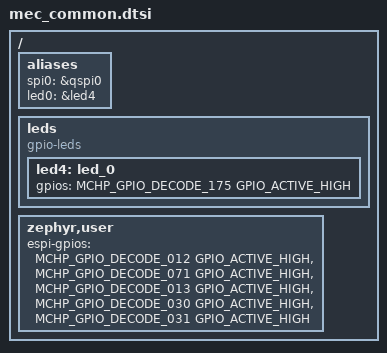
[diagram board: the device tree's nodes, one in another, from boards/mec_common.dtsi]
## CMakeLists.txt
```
# SPDX-License-Identifier: Apache-2.0

cmake_minimum_required(VERSION 3.20.0)

find_package(Zephyr REQUIRED HINTS $ENV{ZEPHYR_BASE})
project(espi_host_emu)

FILE(GLOB app_sources src/*.c)
target_sources(app PRIVATE ${app_sources})
```

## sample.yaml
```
sample:
  name: Exercise eSPI driver with an emulated eSPI host
tests:
  sample.boards.mec_assy6906.espi_host_emu:
    build_only: true
    platform_allow:
      - mec_assy6906_mech1723nlj
      - mec_assy6906_mech1723nsz
    tags: drivers espi
```

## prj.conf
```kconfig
CONFIG_LOG=y
CONFIG_LOG_MODE_IMMEDIATE=y
#CONFIG_LOG_MODE_MINIMAL=y
# !!! WARNING: deferred and buffer size not working.
# !!! log_panic() does not output messages.
#CONFIG_LOG_MODE_DEFERRED=y
#CONFIG_LOG_BUFFER_SIZE=4096
#CONFIG_LOG_BACKEND_SWO=y
#CONFIG_LOG_BACKEND_SWO_FREQ_HZ=4000000

CONFIG_GPIO=y
CONFIG_PINCTRL=y
CONFIG_LED=y
CONFIG_SPI=y
CONFIG_SPI_EXTENDED_MODES=y
CONFIG_SPI_MEC5_QSPI_INTERRUPT=n
CONFIG_SERIAL=y
CONFIG_CONSOLE=y
CONFIG_UART_CONSOLE=y
CONFIG_I2C=y

CONFIG_PM=n

# CONFIG_APP_INVERT_ESPI_CS_N=y

# Help debug new code
# CONFIG_DEBUG_COREDUMP=y
# CONFIG_TRAP_UNALIGNED_ACCESS=y
# CONFIG_SOC_MEC5_DEBUG_AND_TRACING=y
# CONFIG_SOC_MEC5_DEBUG_AND_SWV_TRACING=y
#CONFIG_DEBUG=y
```

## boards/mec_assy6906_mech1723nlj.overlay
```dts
/*
 * Copyright (c) 2023 Microchip Technology Inc.
 *
 * SPDX-License-Identifier: Apache-2.0
 */

/* mec_assy6906 EVB with MEC1723N-LJ daughter card
 * MEC1723 does not have an internal SPI flash.
 * Connect QSPI to external shared SPI flash pins using SHD_nCS1.
 */

#include "mec_common.dtsi"

&pinctrl {
	qspi_shd_cs0_n_gpio055_sleep: qspi_shd_cs0_n_gpio055_sleep {
		pinmux = < MCHP_XEC_PINMUX(055, MCHP_AF2) >;
		low-power-enable;
	};
};

&qspi0 {
	status = "okay";
	pinctrl-0 = < &qspi_shd_cs0_n_gpio055_sleep
		      &qspi_shd_cs1_n_gpio002
		      &qspi_shd_clk_gpio056
		      &qspi_shd_io0_gpio223
		      &qspi_shd_io1_gpio224
		      &qspi_shd_io2_gpio227
		      &qspi_shd_io3_gpio016 >;
	pinctrl-names = "default";
};
```

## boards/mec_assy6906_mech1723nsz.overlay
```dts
/*
 * Copyright (c) 2023 Microchip Technology Inc.
 *
 * SPDX-License-Identifier: Apache-2.0
 */

/* mec_assy6906 EVB with MEC1723N-SZ daughter card
 * MEC1723 does not have an internal SPI flash.
 * Connect QSPI to external shared SPI flash pins using SHD_nCS1.
 */

#include "mec_common.dtsi"

&pinctrl {
	qspi_shd_cs0_n_gpio055_sleep: qspi_shd_cs0_n_gpio055_sleep {
		pinmux = < MCHP_XEC_PINMUX(055, MCHP_AF2) >;
		low-power-enable;
	};
};

&qspi0 {
	status = "okay";
	pinctrl-0 = < &qspi_shd_cs0_n_gpio055_sleep
		      &qspi_shd_cs1_n_gpio002
		      &qspi_shd_clk_gpio056
		      &qspi_shd_io0_gpio223
		      &qspi_shd_io1_gpio224
		      &qspi_shd_io2_gpio227
		      &qspi_shd_io3_gpio016 >;
	pinctrl-names = "default";
};
```

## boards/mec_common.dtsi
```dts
/*
 * Copyright (c) 2023 Microchip Technology Inc.
 *
 * SPDX-License-Identifier: Apache-2.0
 */

#include <zephyr/dt-bindings/gpio/gpio.h>
#include <zephyr/dt-bindings/gpio/microchip-xec-gpio.h>
#include <zephyr/dt-bindings/espi/mchp-mec5-espi.h>

/* Sample for MEC_ASSY6906 board with MEC1723N LJ(176-pin) or SZ(144-pin) CPU card
 * Emulate eSPI using QSPI controller and QSPI SHD_xxx pins.
 * SHD_xxx pins are on VTR2 voltage domain.
 * ESPI pins are on VTR3 (+1.8V) voltage domain on all MEC parts.
 * Configure Assy6906 VTR2 for +1.8V
 * JP42 1-2, JP59 1-2, JP60 2-3, JP61 1-2, JP62 1-2
 *
 * QSPI SHD_xxx pin jumpers:
 * JP156 1-2 Select VTR2 for QSPI header J34
 * JP25 1-2 Select SHD_nCS1 for GPIO002
 * JP23 3x6 2-3, 5-6, 8-9, 11-12, 14-15, 17-18 Select SHD_CLK, SHD_IOn, SHD_nCS0 pins
 *
 * Assy6906 J34 QSPI SHD/PVT SPI header J34
 * We choose SHD_nCS1 because it is not used as a strap.
 * pins 19,20 = VTR2
 * pins 1,5,17,18 = GND		GND
 * pin 10 SHD_nCS1		ESPI_nCS
 * pin 2  SHD_CLK		ESPI_CLK
 * pin 6  SHD_IO0		ESPI_IO0
 * pin 7  SHD_IO1		ESPI_IO1
 * pin 8  SHD_IO2		ESPI_IO2
 * pin 9  SHD_IO3		ESPI_IO3
 *
 * GPIO012(VTR2) J19-3		ESPI_nRESET
 *   output init value = High
 *
 * GPIO013(VTR2) J19-1		ESPI_nALERT
 *   output init value = High
 *
 * NOTE1: Target EVB has 10K pull-ups to VTR3 on all ESPI_xxx pins.
 * Do not enable pull-ups on Assy6906 for these pins.
 * NOTE2: eSPI Target will be configured to use its default in-band reset
 * on ESPI_IO1.  ESPI_nALERT may be used for debug.
 *
 * Emulated Host to Target VCC_PWRGD
 * GPIO030 (VTR1) on J9-1 or J40-6
 * No not install JP77 1-2 7.5K pull-up.
 * Configure GPIO030 as GPIO output initial state = Low
 *
 * Target Ready Input active Low
 * GPIO031 (VTR1) on J40-7
 * Install JP71 21-22 pull-up to VTR1
 * Configure GPIO031 as GPIO input
 *
 */

/ {
	aliases {
		spi0 = &qspi0;
		led0 = &led4;
	};

	leds {
		compatible = "gpio-leds";
		led4: led_0 {
			gpios = <MCHP_GPIO_DECODE_175 GPIO_ACTIVE_HIGH>;
		};
	};

	/* zephyr,user is a special case node for application & test use
	 * This node does not require a YAML binding file.
	 * espi-gpio pins
	 * index 0 = pin connected to ESPI_nRESET allowing app to control reset.
	 * index 1 = eSPI IO[1] GPIO used as eSPI ALERT. eSPI Target controller
	 * drives this pin low when it requires attention. Note: Target can drive
	 * eSPI ALERT pin when eSPI nCS is not asserted.
	 * index 2 = GPIO063 unused dedicated eSPI_nALERT pin. We use as GPIO to
	 * help measure code sequences.
	 * index 3 = GPIO030 used as GPIO output Host-to-Target VCC_PWRGD
	 * index 4 = GPIO031 used as GPIO input Target-nReady
	 * In application code use GPIO_DT_SPEC_GET_BY_IDX() macro.
	 */
	zephyr,user {
		espi-gpios = <MCHP_GPIO_DECODE_012 GPIO_ACTIVE_HIGH>,
			     <MCHP_GPIO_DECODE_071 GPIO_ACTIVE_HIGH>,
			     <MCHP_GPIO_DECODE_013 GPIO_ACTIVE_HIGH>,
			     <MCHP_GPIO_DECODE_030 GPIO_ACTIVE_HIGH>,
			     <MCHP_GPIO_DECODE_031 GPIO_ACTIVE_HIGH>;
	};
};
```

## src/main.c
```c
/*
 * Copyright (c) 2024 Microchip Technology, Inc.
 *
 * SPDX-License-Identifier: Apache-2.0
 */

#include <errno.h>
#include <stdint.h>
#include <string.h>
#include <soc.h>
#include <mec_pcr_api.h>

#include <zephyr/device.h>
#include <zephyr/devicetree.h>
#include <zephyr/kernel.h>
#include <zephyr/drivers/espi.h>
#include <zephyr/drivers/gpio.h>
#include <zephyr/drivers/i2c.h>
#include <zephyr/drivers/led.h>
#include <zephyr/drivers/pinctrl.h>
#include <zephyr/drivers/spi.h>
#include <zephyr/sys/sys_io.h>

#include <zephyr/logging/log_ctrl.h>
#include <zephyr/logging/log.h>
LOG_MODULE_REGISTER(app, CONFIG_LOG_DEFAULT_LEVEL);

#include "espi_debug.h"
#include "espi_hc_emu.h"

struct espi_status_data {
	void *buf;
	uint32_t bufsz;
	uint32_t nitems;
};

#define APP_FLAG_GET_STATUS_LOOP BIT(0)

static volatile uint32_t app_flags;
static volatile uint32_t spin_val;
static volatile int ret_val;
static volatile int app_main_exit;

static struct espi_status_data esd;
static struct espi_hc_context hc;
/* eSPI specification: maximum 64 VWire groups */
/* static struct espi_hc_vw hcvw[64]; */
static struct espi_hc_vw hcvw2[64];

#define ESPI_CHAN_READY_PC_IDX 0
#define ESPI_CHAN_READY_VW_IDX 1
#define ESPI_CHAN_READY_OOB_IDX 2
#define ESPI_CHAN_READY_FC_IDX 3
volatile uint8_t chan_ready[4];

static uint8_t c2t_vw_host_idxs[] = {
	0x02u, 0x03u, 0x07u, 0x41u, 0x42u, 0x43u, 0x44u, 0x47u, 0x4au
};

static void spin_on(uint32_t id, int rval);
static int wait_espi_chan_ready(struct espi_hc_context *pch, uint16_t cfgid, int timeout_cnt);
int app_process_espi_status(struct espi_hc_context *hc, uint16_t espi_status,
			    struct espi_status_data *data);

int main(void)
{
	int ret = 0;
	struct espi_hc_vw vwg = {0};
	uint32_t io_addr_len = 0;
	uint32_t io_data = 0;
	uint32_t chan_config = 0;
	uint16_t cfgid = 0;
	uint16_t cmd_status = 0;

	LOG_INF("MEC5 eSPI Host Controller emulation for board: %s", DT_N_COMPAT_MODEL_IDX_0);

	ret = espi_hc_ctx_emu_init(&hc);
	if (ret) {
		LOG_ERR("eSPI HC CTX EMU init error %d", ret);
		spin_on((uint32_t)__LINE__, ret);
		goto app_exit;
	}

	LOG_INF("Init eSPI HC emulation using QSPI0");
	ret = espi_hc_emu_init(MHZ(4));
	if (ret) {
		spin_on((uint32_t)__LINE__, ret);
		goto app_exit;
	}

	LOG_INF("Wait for Target nREADY");
	do {
		ret = espi_hc_emu_is_target_ready();
	} while (ret == 0);

	LOG_INF("Target signalled Ready. De-assert ESPI_nRESET and send GET_CONFIG");
	ret = espi_hc_ctx_emu_ctrl(&hc, 1);
	if (ret) {
		LOG_ERR("Error eSPI HC emu control (enable)");
		spin_on((uint32_t)__LINE__, ret);
		goto app_exit;
	}

	/* espi_hc_emu_espi_reset_n(1); */

	LOG_INF("Delay 100 ms to allow Target to print debug messages");
	k_sleep(K_MSEC(100));

	/* Get eSPI Device ID */
	LOG_INF("Read eSPI Device ID from Target");
	cfgid = ESPI_GET_CONFIG_DEV_ID;
	ret = espi_hc_ctx_emu_get_config(&hc, cfgid);
	if (ret) {
		LOG_ERR("FAIL: GET_CONFIG %u err (%d)", cfgid, ret);
		spin_on((uint32_t)__LINE__, ret);
		goto app_exit;
	}
	espi_debug_print_cap_word(cfgid, hc.version_id);
	espi_debug_pr_status(hc.pkt_status);

	LOG_INF("Read General Capabilities from Target");
	cfgid = ESPI_GET_CONFIG_GLB_CAP;
	ret = espi_hc_ctx_emu_get_config(&hc, cfgid);
	if (ret) {
		LOG_ERR("FAIL: GET_CONFIG %u err (%d)", cfgid, ret);
		spin_on((uint32_t)__LINE__, ret);
		goto app_exit;
	}
	espi_debug_print_cap_word(cfgid, hc.global_cap_cfg);
	espi_debug_pr_status(hc.pkt_status);

	if ((hc.global_cap_cfg & 0xf) != 0xfu) {
		LOG_ERR("PC, VW, OOB, FC are not all supported!");
		spin_on((uint32_t)__LINE__, ret);
		goto app_exit;
	}

	/* Read VW Capabilities from Target */
	LOG_INF("Read VWire Capabilities from Target");
	cfgid = ESPI_GET_CONFIG_VW_CAP;
	ret = espi_hc_ctx_emu_get_config(&hc, cfgid);
	if (ret) {
		LOG_ERR("FAIL: GET_CONFIG %u err (%d)", cfgid, ret);
		spin_on((uint32_t)__LINE__, ret);
		goto app_exit;
	}
	espi_debug_print_cap_word(cfgid, hc.vw_cap_cfg);
	espi_debug_pr_status(hc.pkt_status);

	/* Update VW Cap-Config
	 * Set Selected number of VW groups = Supported
	 * Enable VW Channel
	 * b[21:16] = operating maximum number of VW groups (R/W)
	 * b[13:8] = maximum number of VW groups the Target HW supports (R/O)
	 * b[1] = VW Channel Ready from Target (R/O)
	 * b[0] = VW Channel Enable set by Host (R/W)
	 */
	LOG_INF("Update VW Cap/Cfg: Set max supported VW groups to 8 and enable VW channel");
	chan_config = hc.vw_cap_cfg;
	chan_config &= ~(0x3fu << 16);
	chan_config |= (0x08u << 16); /* Set operating max to 8 VW groups */
	chan_config |= BIT(0); /* enable VW channel */
	LOG_INF("New VW Caps/Cfg = 0x%08x", chan_config);

	cfgid = ESPI_GET_CONFIG_VW_CAP;
	ret = espi_hc_ctx_emu_set_config(&hc, cfgid, chan_config);
	if (ret) {
		LOG_ERR("FAIL: sET_CONFIG %u err (%d)", cfgid, ret);
		spin_on((uint32_t)__LINE__, ret);
		goto app_exit;
	}
	espi_debug_pr_status(hc.pkt_status);

	LOG_INF("Poll reading VW Config until Target sets VW Ready");
	ret = wait_espi_chan_ready(&hc, cfgid, -1);
	if (ret) {
		goto app_exit;
	}

	espi_debug_print_cap_word(cfgid, hc.vw_cap_cfg);

	LOG_INF("Issue GET_STATUS");
	ret = espi_hc_ctx_get_status(&hc);
	if (ret) {
		LOG_ERR("GET_STATUS failed (%d)", ret);
		spin_on((uint32_t)__LINE__, ret);
		goto app_exit;
	}
	espi_debug_pr_status(hc.pkt_status);

	esd.buf = &hcvw2;
	esd.bufsz = sizeof(hcvw2);
	esd.nitems = 0u;
	ret = app_process_espi_status(&hc, hc.pkt_status, &esd);
	if (ret) {
		LOG_ERR("App process eSPI status: %d", ret);
		spin_on((uint32_t)__LINE__, ret);
		goto app_exit;
	}

	LOG_INF("Read OOB Channel configuration from Target");
	cfgid = ESPI_GET_CONFIG_OOB_CAP;
	ret = espi_hc_ctx_emu_get_config(&hc, cfgid);
	if (ret) {
		LOG_ERR("FAIL: GET_CONFIG %u err (%d)", cfgid, ret);
		spin_on((uint32_t)__LINE__, ret);
		goto app_exit;
	}
	espi_debug_print_cap_word(cfgid, hc.oob_cap_cfg);
	espi_debug_pr_status(hc.pkt_status);

	/* Enable OOB channel with maximum packet size 64 bytes
	 * b[10:8] = OOB message max. payload size (R/W)
	 * b[1] = ready (R/O)
	 * b[0] = enable (R/W)
	 */
	LOG_INF("Update OOB Config: Set max packet size to 64 bytes and enable OOB channel");
	chan_config = hc.oob_cap_cfg;
	LOG_INF("Current OOB Cap/Cfg = 0x%08x", chan_config);
	chan_config &= ~(0x7u << 8);
	chan_config |= (1u << 8); /* b[10:8]=001b is 64 bytes */
	chan_config |= BIT(0); /* enable OOB channel */
	LOG_INF("New OOB Caps/Cfg = 0x%08x", chan_config);

	cfgid = ESPI_GET_CONFIG_OOB_CAP;
	ret = espi_hc_ctx_emu_set_config(&hc, cfgid, chan_config);
	if (ret) {
		LOG_ERR("FAIL: SET_CONFIG %u err (%d)", cfgid, ret);
		spin_on((uint32_t)__LINE__, ret);
		goto app_exit;
	}
	espi_debug_pr_status(hc.pkt_status);

	LOG_INF("Poll reading OOB Config until Target sets OOB Ready");
	ret = wait_espi_chan_ready(&hc, cfgid, -1);
	if (ret) {
		goto app_exit;
	}

	LOG_INF("Issue GET_STATUS");
	ret = espi_hc_ctx_get_status(&hc);
	if (ret) {
		LOG_ERR("GET_STATUS failed (%d)", ret);
		spin_on((uint32_t)__LINE__, ret);
		goto app_exit;
	}
	espi_debug_pr_status(hc.pkt_status);

	esd.buf = &hcvw2;
	esd.bufsz = sizeof(hcvw2);
	esd.nitems = 0u;
	ret = app_process_espi_status(&hc, hc.pkt_status, &esd);
	if (ret) {
		LOG_ERR("App process eSPI status: %d", ret);
		spin_on((uint32_t)__LINE__, ret);
		goto app_exit;
	}

	/* Based on soft-straps reconfigure VW and OOB channels
	 * Increase VW operating max. groups to 0x3f
	 * No change to OOB. All we could do is increase max payload size.
	 */
	LOG_INF("Update VW Cap/Cfg: Set max supported VW groups to 0x3f");
	chan_config = hc.vw_cap_cfg;
	LOG_INF("Current VW Cap/Cfg = 0x%08x", chan_config);
	chan_config &= ~(0x3fu << 16);
	chan_config |= (0x3fu << 16); /* Set operating max to 63 VW groups */
	LOG_INF("New VW Caps/Cfg = 0x%08x", chan_config);

	cfgid = ESPI_GET_CONFIG_VW_CAP;
	ret = espi_hc_ctx_emu_set_config(&hc, cfgid, chan_config);
	if (ret) {
		LOG_ERR("FAIL: VW SET_CONFIG (%d)", ret);
		spin_on((uint32_t)__LINE__, ret);
		goto app_exit;
	}
	espi_debug_pr_status(hc.pkt_status);

	LOG_INF("Issue GET_STATUS");
	ret = espi_hc_ctx_get_status(&hc);
	if (ret) {
		LOG_ERR("GET_STATUS failed (%d)", ret);
		spin_on((uint32_t)__LINE__, ret);
		goto app_exit;
	}

	espi_debug_pr_status(hc.pkt_status);

	esd.buf = &hcvw2;
	esd.bufsz = sizeof(hcvw2);
	esd.nitems = 0u;
	ret = app_process_espi_status(&hc, hc.pkt_status, &esd);
	if (ret) {
		LOG_ERR("App process eSPI status: %d", ret);
		spin_on((uint32_t)__LINE__, ret);
		goto app_exit;
	}

	/* Enable Flash Channel
	 * Set b[14:12]=001b max. read request size of 64 bytes
	 * Set b[11]=0b CAFS
	 * Set b[10:8]=001b max max payload size of 64 bytes
	 * Set b[4:2]=001b flash block erase size 4KB
	 * b[1]=ready (R/O)
	 * b[0]=enable (R/W)
	 */
	LOG_INF("Update FC Cap/Cfg and enable");
	chan_config = hc.fc_cap_cfg;
	LOG_INF("Current FC Cap/Cfg = 0x%08x", chan_config);
	chan_config &= ~((0x7u << 12) | BIT(11) | (0x7u << 8) | (0x7u << 2));
	chan_config |= ((1u << 12) | (1u << 8) | (1u << 2) | BIT(0));
	LOG_INF("New VW Caps/Cfg = 0x%08x", chan_config);

	cfgid = ESPI_GET_CONFIG_FC_CAP;
	ret = espi_hc_ctx_emu_set_config(&hc, cfgid, chan_config);
	if (ret) {
		LOG_ERR("FAIL: FC SET_CONFIG (%d)", ret);
		spin_on((uint32_t)__LINE__, ret);
		goto app_exit;
	}
	espi_debug_pr_status(hc.pkt_status);

	LOG_INF("Poll reading FC Config until Target sets FC Ready");
	ret = wait_espi_chan_ready(&hc, cfgid, -1);
	if (ret) {
		goto app_exit;
	}

	LOG_INF("Issue GET_STATUS");
	ret = espi_hc_ctx_get_status(&hc);
	if (ret) {
		LOG_ERR("GET_STATUS failed (%d)", ret);
		spin_on((uint32_t)__LINE__, ret);
		goto app_exit;
	}
	espi_debug_pr_status(hc.pkt_status);

	esd.buf = &hcvw2;
	esd.bufsz = sizeof(hcvw2);
	esd.nitems = 0u;
	ret = app_process_espi_status(&hc, hc.pkt_status, &esd);
	if (ret) {
		LOG_ERR("App process eSPI status: %d", ret);
		spin_on((uint32_t)__LINE__, ret);
		goto app_exit;
	}

	k_sleep(K_MSEC(100));

	LOG_INF("Issue GET_STATUS");
	ret = espi_hc_ctx_get_status(&hc);
	if (ret) {
		LOG_ERR("GET_STATUS failed (%d)", ret);
		spin_on((uint32_t)__LINE__, ret);
		goto app_exit;
	}
	espi_debug_pr_status(hc.pkt_status);

	esd.buf = &hcvw2;
	esd.bufsz = sizeof(hcvw2);
	esd.nitems = 0u;
	ret = app_process_espi_status(&hc, hc.pkt_status, &esd);
	if (ret) {
		LOG_ERR("App process eSPI status: %d", ret);
		spin_on((uint32_t)__LINE__, ret);
		goto app_exit;
	}

	memset(&vwg, 0, sizeof(vwg));
	ret = espi_hc_get_vw_group_data(&hc, 5u, &vwg);
	if (ret) {
		LOG_ERR("Could not find VWire at Host Index 5h. (%d)", ret);
		spin_on((uint32_t)__LINE__, ret);
		goto app_exit;
	}

	if ((vwg.valid & (BIT(0) | BIT(3))) == (BIT(0) | BIT(3))) {
		LOG_INF("TARGET_BOOT_LOAD_DONE/STATUS are valid");
		LOG_INF("TARGET_BOOT_LOAD_DONE = %lu", (vwg.levels & BIT(0)));
		LOG_INF("TARGET_BOOT_LOAD_DONE_STATUS = %lu", ((vwg.levels & BIT(3)) >> 3));
		if ((vwg.levels & (BIT(0) | BIT(3))) == (BIT(0) | BIT(3))) {
			LOG_INF("Both VWires set by Target as expected");
		} else {
			LOG_ERR("Target did not set TARGET_BOOT_LOAD_DONE/STATUS "
				"to expected values");
			spin_on((uint32_t)__LINE__, ret);
			goto app_exit;
		}
	} else {
		LOG_ERR("TARGET_BOOT_LOAD_DONE/STATUS VWire values are not valid!");
		spin_on((uint32_t)__LINE__, ret);
		goto app_exit;
	}

	LOG_INF("Send default values of all Controller-to-Target VWires");
	ret = espi_hc_ctx_emu_put_mult_host_index(&hc, c2t_vw_host_idxs,
						  ARRAY_SIZE(c2t_vw_host_idxs),
						  ESPI_HC_EMU_PUT_VW_RST_VAL);
	if (ret) {
		LOG_ERR("C2T PUT_VW reset values failed (%d)", ret);
		spin_on((uint32_t)__LINE__, ret);
		goto app_exit;
	}

	LOG_INF("Issue GET_STATUS");
	ret = espi_hc_ctx_get_status(&hc);
	if (ret) {
		LOG_ERR("GET_STATUS failed (%d)", ret);
		spin_on((uint32_t)__LINE__, ret);
		goto app_exit;
	}
	espi_debug_pr_status(hc.pkt_status);

	esd.buf = &hcvw2;
	esd.bufsz = sizeof(hcvw2);
	esd.nitems = 0u;
	ret = app_process_espi_status(&hc, hc.pkt_status, &esd);
	if (ret) {
		LOG_ERR("App process eSPI status: %d", ret);
		spin_on((uint32_t)__LINE__, ret);
		goto app_exit;
	}

	/* Host set Target's VCC_PWRGD input High */
	ret = espi_hc_emu_vcc_pwrgd(1);
	if (ret) {
		LOG_ERR("Set VCC_PWRGD error: %d", ret);
		spin_on((uint32_t)__LINE__, ret);
		goto app_exit;
	}

	/* PUT_VWIRE SUS_WARN# = 1. Host index 0x41 bit 0 */
	LOG_INF("Host send C2T nSUS_WARN = 1");
	ret = espi_hc_set_ct_vwire(&hc, 0x41u, 0, 1);
	if (ret) {
		LOG_ERR("In HC CTX set SUS_WARN# = 1 error %d", ret);
		spin_on((uint32_t)__LINE__, ret);
		goto app_exit;
	}
	ret = espi_hc_ctx_emu_put_host_index(&hc, 0x41u);
	if (ret) {
		LOG_ERR("PUT_VW Host Index 0x41 error %d", ret);
		spin_on((uint32_t)__LINE__, ret);
		goto app_exit;
	}

	/* Send VW nSLP_S5=1. Host index 0x02 bit 2 */
	LOG_INF("Host send C2T nSLP_S5 = 1");
	ret = espi_hc_set_ct_vwire(&hc, 0x02u, 2, 1);
	if (ret) {
		LOG_ERR("In HC CTX set SLP_S5# = 1 error %d", ret);
		spin_on((uint32_t)__LINE__, ret);
		goto app_exit;
	}
	ret = espi_hc_ctx_emu_put_host_index(&hc, 0x02u);
	if (ret) {
		LOG_ERR("PUT_VW Host Index 0x02 error %d", ret);
		spin_on((uint32_t)__LINE__, ret);
		goto app_exit;
	}

	/* Send VW nSLP_S4=1. Host index 0x02 bit 1 */
	LOG_INF("Host send C2T nSLP_S4 = 1");
	ret = espi_hc_set_ct_vwire(&hc, 0x02u, 1, 1);
	if (ret) {
		LOG_ERR("In HC CTX set SLP_S4# = 1 error %d", ret);
		spin_on((uint32_t)__LINE__, ret);
		goto app_exit;
	}
	ret = espi_hc_ctx_emu_put_host_index(&hc, 0x02u);
	if (ret) {
		LOG_ERR("PUT_VW Host Index 0x02 error %d", ret);
		spin_on((uint32_t)__LINE__, ret);
		goto app_exit;
	}

	/* Send VW nSLP_S3=1, Host index 0x02 bit 0 */
	LOG_INF("Host send C2T nSLP_S3 = 1");
	ret = espi_hc_set_ct_vwire(&hc, 0x02u, 0, 1);
	if (ret) {
		LOG_ERR("In HC CTX set SLP_S3# = 1 error %d", ret);
		spin_on((uint32_t)__LINE__, ret);
		goto app_exit;
	}
	ret = espi_hc_ctx_emu_put_host_index(&hc, 0x02u);
	if (ret) {
		LOG_ERR("PUT_VW Host Index 0x02 error %d", ret);
		spin_on((uint32_t)__LINE__, ret);
		goto app_exit;
	}

	/* Send VW nSLP_A=1, Host index 0x41 bit 3 */
	LOG_INF("Host send C2T nSLP_A = 1");
	ret = espi_hc_set_ct_vwire(&hc, 0x41u, 3, 1);
	if (ret) {
		LOG_ERR("In HC CTX set SLP_A# = 1 error %d", ret);
		spin_on((uint32_t)__LINE__, ret);
		goto app_exit;
	}
	ret = espi_hc_ctx_emu_put_host_index(&hc, 0x41u);
	if (ret) {
		LOG_ERR("PUT_VW Host Index 0x41 error %d", ret);
		spin_on((uint32_t)__LINE__, ret);
		goto app_exit;
	}

	/* Send VW nSLP_LAN=1, Host index 0x42 bit 0 */
	LOG_INF("Host send C2T nSLP_LAN = 1");
	ret = espi_hc_set_ct_vwire(&hc, 0x42u, 0, 1);
	if (ret) {
		LOG_ERR("In HC CTX set SLP_LAN# = 1 error %d", ret);
		spin_on((uint32_t)__LINE__, ret);
		goto app_exit;
	}
	ret = espi_hc_ctx_emu_put_host_index(&hc, 0x42u);
	if (ret) {
		LOG_ERR("PUT_VW Host Index 0x42 error %d", ret);
		spin_on((uint32_t)__LINE__, ret);
		goto app_exit;
	}

	/* Send VW nSLP_WLAN=1, Host index 0x42 bit 1 */
	LOG_INF("Host send C2T nSLP_WLAN = 1");
	ret = espi_hc_set_ct_vwire(&hc, 0x42u, 1, 1);
	if (ret) {
		LOG_ERR("In HC CTX set SLP_WLAN# = 1 error %d", ret);
		spin_on((uint32_t)__LINE__, ret);
		goto app_exit;
	}
	ret = espi_hc_ctx_emu_put_host_index(&hc, 0x42u);
	if (ret) {
		LOG_ERR("PUT_VW Host Index 0x42 error %d", ret);
		spin_on((uint32_t)__LINE__, ret);
		goto app_exit;
	}

	/* Send nSUS_STAT=1 and nPLTRST=1
	 * nSUS_STAT Host index 0x03 bit 0
	 * nPLTRST Host index 0x03 bit 1
	 */
	LOG_INF("Host send C2T nSLP_WLAN = 1 and nPLTRST = 1");
	ret = espi_hc_set_ct_vwire(&hc, 0x03u, 0, 1);
	if (ret) {
		LOG_ERR("In HC CTX set SUS_STAT# = 1 error %d", ret);
		spin_on((uint32_t)__LINE__, ret);
		goto app_exit;
	}
	ret = espi_hc_set_ct_vwire(&hc, 0x03u, 1, 1);
	if (ret) {
		LOG_ERR("In HC CTX set PLTRST# = 1 error %d", ret);
		spin_on((uint32_t)__LINE__, ret);
		goto app_exit;
	}
	ret = espi_hc_ctx_emu_put_host_index(&hc, 0x03u);
	if (ret) {
		LOG_ERR("PUT_VW Host Index 0x03 error %d", ret);
		spin_on((uint32_t)__LINE__, ret);
		goto app_exit;
	}

	k_sleep(K_MSEC(50));

	/* write 1-byte to I/O 0x62 currently mapped to EC ACPI_EC0 */
	io_addr_len = 0x10062u;
	io_data = 0x5Au;
	cmd_status = 0u;
	LOG_INF("Write to ACPI_EC0 I/O: 1 byte data = 0x%02x", io_data);
	ret = espi_hc_emu_put_iowr(&hc, io_addr_len, io_data, &cmd_status);
	if (ret) {
		LOG_ERR("eSPI EMU PUT_IOWR error %d", ret);
		spin_on((uint32_t)__LINE__, ret);
		goto app_exit;
	}

	io_addr_len = 0x10080u;
	io_data = 0x69u;
	cmd_status = 0u;
	LOG_INF("8-bit Write I/O Port 0x%02x = 0x%02x", io_addr_len, io_data);
	ret = espi_hc_emu_put_iowr(&hc, io_addr_len, io_data, &cmd_status);
	if (ret) {
		LOG_ERR("eSPI EMU PUT_IOWR error %d", ret);
		spin_on((uint32_t)__LINE__, ret);
		goto app_exit;
	}

	k_sleep(K_MSEC(50));


	io_addr_len = 0x10081u;
	io_data = 0x6Au;
	cmd_status = 0u;
	LOG_INF("8-bit Write I/O Port 0x%02x = 0x%02x", io_addr_len, io_data);
	ret = espi_hc_emu_put_iowr(&hc, io_addr_len, io_data, &cmd_status);
	if (ret) {
		LOG_ERR("eSPI EMU PUT_IOWR error %d", ret);
		spin_on((uint32_t)__LINE__, ret);
		goto app_exit;
	}

	k_sleep(K_MSEC(50));

	io_addr_len = 0x10082u;
	io_data = 0x6Bu;
	cmd_status = 0u;
	LOG_INF("8-bit Write I/O Port 0x%02x = 0x%02x", io_addr_len, io_data);
	ret = espi_hc_emu_put_iowr(&hc, io_addr_len, io_data, &cmd_status);
	if (ret) {
		LOG_ERR("eSPI EMU PUT_IOWR error %d", ret);
		spin_on((uint32_t)__LINE__, ret);
		goto app_exit;
	}

	k_sleep(K_MSEC(50));

	io_addr_len = 0x10083u;
	io_data = 0x6Cu;
	cmd_status = 0u;
	LOG_INF("8-bit Write I/O Port 0x%02x = 0x%02x", io_addr_len, io_data);
	ret = espi_hc_emu_put_iowr(&hc, io_addr_len, io_data, &cmd_status);
	if (ret) {
		LOG_ERR("eSPI EMU PUT_IOWR error %d", ret);
		spin_on((uint32_t)__LINE__, ret);
		goto app_exit;
	}

	k_sleep(K_MSEC(50));

	io_addr_len = 0x20080u;
	io_data = 0x4321u;
	cmd_status = 0u;
	LOG_INF("16-bit Write I/O Port 0x%02x = 0x%04x", io_addr_len, io_data);
	ret = espi_hc_emu_put_iowr(&hc, io_addr_len, io_data, &cmd_status);
	if (ret) {
		LOG_ERR("eSPI EMU PUT_IOWR error %d", ret);
		spin_on((uint32_t)__LINE__, ret);
		goto app_exit;
	}

	k_sleep(K_MSEC(50));

	io_addr_len = 0x20082u;
	io_data = 0x9876u;
	cmd_status = 0u;
	LOG_INF("16-bit Write I/O Port 0x%02x = 0x%04x", io_addr_len, io_data);
	ret = espi_hc_emu_put_iowr(&hc, io_addr_len, io_data, &cmd_status);
	if (ret) {
		LOG_ERR("eSPI EMU PUT_IOWR error %d", ret);
		spin_on((uint32_t)__LINE__, ret);
		goto app_exit;
	}

	k_sleep(K_MSEC(50));

	io_addr_len = 0x20081u;
	io_data = 0xA987u;
	cmd_status = 0u;
	LOG_INF("16-bit Write I/O Port 0x%02x = 0x%04x", io_addr_len, io_data);
	ret = espi_hc_emu_put_iowr(&hc, io_addr_len, io_data, &cmd_status);
	if (ret) {
		LOG_ERR("eSPI EMU PUT_IOWR error %d", ret);
		spin_on((uint32_t)__LINE__, ret);
		goto app_exit;
	}

	k_sleep(K_MSEC(50));

	io_addr_len = 0x40080u;
	io_data = 0x99887766u;
	cmd_status = 0u;
	LOG_INF("32-bit Write I/O Port 0x%02x = 0x%08x", io_addr_len, io_data);
	ret = espi_hc_emu_put_iowr(&hc, io_addr_len, io_data, &cmd_status);
	if (ret) {
		LOG_ERR("eSPI EMU PUT_IOWR error %d", ret);
		spin_on((uint32_t)__LINE__, ret);
		goto app_exit;
	}

	k_sleep(K_MSEC(50));

	app_flags |= APP_FLAG_GET_STATUS_LOOP;
	if (app_flags & APP_FLAG_GET_STATUS_LOOP) {
		LOG_INF("Application loop issuing eSPI GET_STATUS");
	}

	while (app_flags & APP_FLAG_GET_STATUS_LOOP) {
		ret = espi_hc_ctx_get_status(&hc);
		if (ret) {
			LOG_ERR("GET_STATUS failed (%d)", ret);
			spin_on((uint32_t)__LINE__, ret);
			goto app_exit;
		}
		if (hc.pkt_status & ESPI_STATUS_ALL_AVAIL) {
			esd.buf = &hcvw2;
			esd.bufsz = sizeof(hcvw2);
			esd.nitems = 0u;
			ret = app_process_espi_status(&hc, hc.pkt_status, &esd);
		}

		k_sleep(K_MSEC(200));
	}

	LOG_INF("Application Done");
	spin_val = 99u;
	while (spin_val) {
		k_sleep(K_MSEC(100));
	}

app_exit:
	LOG_INF("App Exit");
	log_panic();
	app_main_exit = 1;

	return 0;
}

static void spin_on(uint32_t id, int rval)
{
	spin_val = id;
	ret_val = rval;

	LOG_INF("Spin code %u", id);
	/* log_panic(); flush log buffers */

	while (spin_val) {
		;
	}
}

int app_process_espi_status(struct espi_hc_context *hc, uint16_t espi_status,
			    struct espi_status_data *data)
{
	int rc = 0;
	uint8_t nvw_recv = 0;

	if (!hc || !data) {
		return -EINVAL;
	}

	LOG_INF("Process eSPI protocol status = 0x%04x", espi_status);
	if (espi_status & BIT(ESPI_STATUS_VW_AVAIL_POS)) {
		LOG_INF("VWires available: Read VW groups");

		struct espi_hc_vw *vws = (struct espi_hc_vw *)data->buf;
		uint32_t nvws = data->bufsz / sizeof(struct espi_hc_vw);

		rc = espi_hc_ctx_emu_get_vws(hc, vws, (uint8_t)(nvws & 0xffu), &nvw_recv);
		if (rc) {
			return rc;
		}
		data->nitems = nvw_recv;
		rc = espi_hc_ctx_emu_update_t2c_vw(hc, vws, nvw_recv);
		if (rc) {
			LOG_ERR("eSPI HC CTX update T2C error %d", rc);
			return rc;
		}
		espi_debug_print_vws(hc->t2c_vw, ESPI_MAX_TC_VW_GROUPS);
	}
	if (espi_status & BIT(ESPI_STATUS_PC_AVAIL_POS)) {
		LOG_INF("PC available");
		/* TODO Issue GET_PC */
	}
	if (espi_status & BIT(ESPI_STATUS_PC_NP_AVAIL_POS)) {
		LOG_INF("PC NP available");
		/* TODO Issue GET_NP */
	}
	if (espi_status & BIT(ESPI_STATUS_OOB_AVAIL_POS)) {
		LOG_INF("OOB available");
		/* TODO Issue GET_OOB */
	}
	if (espi_status & BIT(ESPI_STATUS_FC_AVAIL_POS)) {
		LOG_INF("FC available");
		/* TODO Issue GET_FC */
	}
	if (espi_status & BIT(ESPI_STATUS_FC_NP_AVAIL_POS)) {
		LOG_INF("FC NP available");
		/* TODO Issue GET_FC_NP */
	}

	return 0;
}

static int wait_espi_chan_ready(struct espi_hc_context *pch, uint16_t cfgid, int timeout_cnt)
{
	uint32_t *pcfg = NULL;
	int ret = 0;

	switch (cfgid) {
	case ESPI_GET_CONFIG_PC_CAP:
		pcfg = &pch->pc_cap_cfg;
		break;
	case ESPI_GET_CONFIG_VW_CAP:
		pcfg = &pch->vw_cap_cfg;
		break;
	case ESPI_GET_CONFIG_OOB_CAP:
		pcfg = &pch->oob_cap_cfg;
		break;
	case ESPI_GET_CONFIG_FC_CAP:
		pcfg = &pch->fc_cap_cfg;
		break;
	default:
		return -EINVAL;
	}

	do {
		ret = espi_hc_ctx_emu_get_config(&hc, cfgid);
		if (ret) {
			LOG_ERR("FAIL: GET_CONFIG %u err (%d)", cfgid, ret);
			return -EIO;
		}
		/* Ready is bit[1] for all channels */
		if (*pcfg & BIT(1)) {
			LOG_INF("Target set Channel Ready = 1");
			return 0;
		}
		k_sleep(K_MSEC(20));
		if (timeout_cnt == 0) {
			break;
		} else if (timeout_cnt > 0) {
			timeout_cnt--;
		}
	} while (1);

	LOG_ERR("TIMEOUT Target did not set Channel Ready to 1");
	return -ETIMEDOUT;
}
```

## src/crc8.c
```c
/**
 * \file
 * Functions and types for CRC checks.
 *
 * Generated on Sat Jul  1 19:43:22 2023
 * by pycrc v0.10.0, https://pycrc.org
 * using the configuration:
 *  - Width         = 8
 *  - Poly          = 0x07
 *  - XorIn         = 0x00
 *  - ReflectIn     = False
 *  - XorOut        = 0x00
 *  - ReflectOut    = False
 *  - Algorithm     = table-driven
 */
#include "crc8.h"     /* include the header file generated with pycrc */
#include <stdlib.h>
#include <stdint.h>



/**
 * Static table used for the table_driven implementation.
 */
static const uint8_t crc8_table[256] = {
0x00, 0x07, 0x0e, 0x09, 0x1c, 0x1b, 0x12, 0x15, 0x38, 0x3f, 0x36, 0x31, 0x24, 0x23, 0x2a, 0x2d,
0x70, 0x77, 0x7e, 0x79, 0x6c, 0x6b, 0x62, 0x65, 0x48, 0x4f, 0x46, 0x41, 0x54, 0x53, 0x5a, 0x5d,
0xe0, 0xe7, 0xee, 0xe9, 0xfc, 0xfb, 0xf2, 0xf5, 0xd8, 0xdf, 0xd6, 0xd1, 0xc4, 0xc3, 0xca, 0xcd,
0x90, 0x97, 0x9e, 0x99, 0x8c, 0x8b, 0x82, 0x85, 0xa8, 0xaf, 0xa6, 0xa1, 0xb4, 0xb3, 0xba, 0xbd,
0xc7, 0xc0, 0xc9, 0xce, 0xdb, 0xdc, 0xd5, 0xd2, 0xff, 0xf8, 0xf1, 0xf6, 0xe3, 0xe4, 0xed, 0xea,
0xb7, 0xb0, 0xb9, 0xbe, 0xab, 0xac, 0xa5, 0xa2, 0x8f, 0x88, 0x81, 0x86, 0x93, 0x94, 0x9d, 0x9a,
0x27, 0x20, 0x29, 0x2e, 0x3b, 0x3c, 0x35, 0x32, 0x1f, 0x18, 0x11, 0x16, 0x03, 0x04, 0x0d, 0x0a,
0x57, 0x50, 0x59, 0x5e, 0x4b, 0x4c, 0x45, 0x42, 0x6f, 0x68, 0x61, 0x66, 0x73, 0x74, 0x7d, 0x7a,
0x89, 0x8e, 0x87, 0x80, 0x95, 0x92, 0x9b, 0x9c, 0xb1, 0xb6, 0xbf, 0xb8, 0xad, 0xaa, 0xa3, 0xa4,
0xf9, 0xfe, 0xf7, 0xf0, 0xe5, 0xe2, 0xeb, 0xec, 0xc1, 0xc6, 0xcf, 0xc8, 0xdd, 0xda, 0xd3, 0xd4,
0x69, 0x6e, 0x67, 0x60, 0x75, 0x72, 0x7b, 0x7c, 0x51, 0x56, 0x5f, 0x58, 0x4d, 0x4a, 0x43, 0x44,
0x19, 0x1e, 0x17, 0x10, 0x05, 0x02, 0x0b, 0x0c, 0x21, 0x26, 0x2f, 0x28, 0x3d, 0x3a, 0x33, 0x34,
0x4e, 0x49, 0x40, 0x47, 0x52, 0x55, 0x5c, 0x5b, 0x76, 0x71, 0x78, 0x7f, 0x6a, 0x6d, 0x64, 0x63,
0x3e, 0x39, 0x30, 0x37, 0x22, 0x25, 0x2c, 0x2b, 0x06, 0x01, 0x08, 0x0f, 0x1a, 0x1d, 0x14, 0x13,
0xae, 0xa9, 0xa0, 0xa7, 0xb2, 0xb5, 0xbc, 0xbb, 0x96, 0x91, 0x98, 0x9f, 0x8a, 0x8d, 0x84, 0x83,
0xde, 0xd9, 0xd0, 0xd7, 0xc2, 0xc5, 0xcc, 0xcb, 0xe6, 0xe1, 0xe8, 0xef, 0xfa, 0xfd, 0xf4, 0xf3
};


uint8_t crc8_update(uint8_t crc, const void *data, size_t data_len)
{
	const uint8_t *d = (const uint8_t *)data;
	unsigned int tbl_idx;

	while (data_len--) {
		tbl_idx = crc ^ *d;
		crc = crc8_table[tbl_idx] & 0xff;
		d++;
	}
	return crc & 0xff;
}
```

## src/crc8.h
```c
/**
 * \file
 * Functions and types for CRC checks.
 *
 * Generated on Sat Jul  1 19:43:09 2023
 * by pycrc v0.10.0, https://pycrc.org
 * using the configuration:
 *  - Width         = 8
 *  - Poly          = 0x07
 *  - XorIn         = 0x00
 *  - ReflectIn     = False
 *  - XorOut        = 0x00
 *  - ReflectOut    = False
 *  - Algorithm     = table-driven
 *
 * This file defines the functions crc_init(), crc_update() and crc_finalize().
 *
 * The crc_init() function returns the initial \c crc value and must be called
 * before the first call to crc_update().
 * Similarly, the crc_finalize() function must be called after the last call
 * to crc_update(), before the \c crc is being used.
 * is being used.
 *
 * The crc_update() function can be called any number of times (including zero
 * times) in between the crc_init() and crc_finalize() calls.
 *
 * This pseudo-code shows an example usage of the API:
 * \code{.c}
 * crc_t crc;
 * unsigned char data[MAX_DATA_LEN];
 * size_t data_len;
 *
 * crc = crc_init();
 * while ((data_len = read_data(data, MAX_DATA_LEN)) > 0) {
 *     crc = crc_update(crc, data, data_len);
 * }
 * crc = crc_finalize(crc);
 * \endcode
 */
#ifndef CRC8_H
#define CRC8_H

#include <stdlib.h>
#include <stdint.h>

#ifdef __cplusplus
extern "C" {
#endif


/**
 * The definition of the used algorithm.
 *
 * This is not used anywhere in the generated code, but it may be used by the
 * application code to call algorithm-specific code, if desired.
 */
#define CRC_ALGO_TABLE_DRIVEN 1


/**
 * The type of the CRC values.
 *
 * This type must be big enough to contain at least 8 bits.
 */
/* typedef uint_fast8_t crc_t; */


/**
 * Calculate the initial crc value.
 *
 * \return     The initial crc value.
 */
static inline uint8_t crc8_init(void)
{
	return 0x00;
}


/**
 * Update the crc value with new data.
 *
 * \param[in] crc      The current crc value.
 * \param[in] data     Pointer to a buffer of \a data_len bytes.
 * \param[in] data_len Number of bytes in the \a data buffer.
 * \return             The updated crc value.
 */
uint8_t crc8_update(uint8_t crc, const void *data, size_t data_len);


/**
 * Calculate the final crc value.
 *
 * \param[in] crc  The current crc value.
 * \return     The final crc value.
 */
static inline uint8_t crc8_finalize(uint8_t crc)
{
	return crc;
}


#ifdef __cplusplus
} /* closing brace for extern "C" */
#endif

#endif /* CRC8_H */
```

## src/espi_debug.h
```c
/*
 * Copyright (c) 2023 Microchip Technology, Inc.
 *
 * SPDX-License-Identifier: Apache-2.0
 */

#ifndef __SAMPLES_BOARDS_MEC_ASSY6906_ESPI_DEBUG_H_
#define __SAMPLES_BOARDS_MEC_ASSY6906_ESPI_DEBUG_H_

#include <stdint.h>
#include "espi_hc_emu.h"

void espi_debug_pr_status(uint16_t espi_status);
void espi_debug_print_cap_word(uint16_t cap_offset, uint32_t cap);
void espi_debug_print_hc(struct espi_hc_context *hc, uint8_t decode_caps);
void espi_debug_print_vws(struct espi_hc_vw *vws, size_t nvws);
const char *get_vw_name(uint32_t vwire_enum_val);

#endif /* __SAMPLES_BOARDS_MEC_ASSY6906_ESPI_DEBUG_H_ */
```

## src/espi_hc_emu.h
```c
/*
 * Copyright (c) 2024 Microchip Technology, Inc.
 *
 * SPDX-License-Identifier: Apache-2.0
 */

#ifndef __SAMPLES_BOARDS_MEC_ASSY6906_ESPI_HC_EMU_H_
#define __SAMPLES_BOARDS_MEC_ASSY6906_ESPI_HC_EMU_H_

#include <stdint.h>
#include <stddef.h>

int espi_hc_emu_init(uint32_t freqhz);
int espi_hc_emu_espi_reset_n(uint8_t level);
int espi_hc_emu_vcc_pwrgd(uint8_t level);
int espi_hc_emu_is_target_ready(void);

int espi_hc_is_alert(void);
int espi_hc_emu_xfr(const uint8_t *msg, size_t msglen, uint8_t *response, size_t resplen);

#define ESPI_HC_EMU_MSG_BUFF_LEN		256u
#define ESPI_HC_EMU_RESP_BUFF_LEN		256u

/* 16-bit GET_CONFIGURATION addresses */
#define ESPI_GET_CONFIG_DEV_ID			0x04u
#define ESPI_GET_CONFIG_GLB_CAP			0x08u
#define ESPI_GET_CONFIG_PC_CAP			0x10u
#define ESPI_GET_CONFIG_VW_CAP			0x20u
#define ESPI_GET_CONFIG_OOB_CAP			0x30u
#define ESPI_GET_CONFIG_FC_CAP			0x40u

/* 16-bit eSPI Status bit definitions */
#define ESPI_STATUS_PC_FREE_POS			0
#define ESPI_STATUS_PC_NP_FREE_POS		1
#define ESPI_STATUS_VW_FREE_POS			2
#define ESPI_STATUS_OOB_FREE_POS		3
#define ESPI_STATUS_PC_AVAIL_POS		4
#define ESPI_STATUS_PC_NP_AVAIL_POS		5
#define ESPI_STATUS_VW_AVAIL_POS		6
#define ESPI_STATUS_OOB_AVAIL_POS		7
#define ESPI_STATUS_FC_FREE_POS			8
#define ESPI_STATUS_FC_NP_FREE_POS		9
#define ESPI_STATUS_FC_AVAIL_POS		12
#define ESPI_STATUS_FC_NP_AVAIL_POS		13

#define ESPI_STATUS_ALL_AVAIL			\
	(BIT(ESPI_STATUS_PC_AVAIL_POS) | BIT(ESPI_STATUS_PC_NP_AVAIL_POS) | \
	 BIT(ESPI_STATUS_VW_AVAIL_POS) | BIT(ESPI_STATUS_OOB_AVAIL_POS) | \
	 BIT(ESPI_STATUS_FC_AVAIL_POS) | BIT(ESPI_STATUS_FC_NP_AVAIL_POS))

#define ESPI_VW_FLAG_DIR_CT 0x1

/* Host context VWire structure */
struct espi_hc_vw {
	uint8_t host_index;
	uint8_t mask;
	uint8_t reset_val;
	uint8_t levels;
	uint8_t valid;
	uint8_t rsvd[3];
};

/* MEC5 eSPI Target has 11 Controller-to-Target and 11
 * Target-to-Controller group registers.
 * We add two for eSPI Host indices 0 and 1 which are
 * used for Serial IRQ for Target-to-Controller.
 * Format of C2T and T2C VWires (except Serial IRQ)
 *   b[7:4]=valid
 *   b[3:0]=wire value 0=low, 1=high
 *
 * Format of Serial IRQ:
 *   b[7]=interrupt level: 0=low, 1=high(interrupt assertion)
 *   b[6:0]=interrupt line
 *          Host Index 0: IRQ 0-127
 *          Host Index 1: IRQ 128-255
 */

#define ESPI_MAX_CT_VW_GROUPS		(11)
#define ESPI_MAX_TC_VW_GROUPS		(11 + 2)

struct espi_msg_pkt {
	uint8_t buf[ESPI_HC_EMU_MSG_BUFF_LEN];
	uint16_t msglen;
	uint8_t msgofs;
	uint8_t crc8;
};

struct espi_resp_pkt {
	uint8_t buf[ESPI_HC_EMU_RESP_BUFF_LEN];
	uint32_t recvlen;
};

struct espi_hc_context {
	uint32_t version_id;
	uint32_t global_cap_cfg;
	uint32_t pc_cap_cfg;
	uint32_t vw_cap_cfg;
	uint32_t oob_cap_cfg;
	uint32_t fc_cap_cfg;
	uint32_t other_cfg;
	uint16_t pkt_status;
	uint8_t vwg_cnt_max;
	uint8_t vwg_cnt;
	struct espi_hc_vw c2t_vw[ESPI_MAX_CT_VW_GROUPS];
	struct espi_hc_vw t2c_vw[ESPI_MAX_TC_VW_GROUPS];
	struct espi_msg_pkt emsg;
	struct espi_resp_pkt ersp;
};

int espi_hc_ctx_emu_init(struct espi_hc_context *hc);

int espi_hc_ctx_emu_ctrl(struct espi_hc_context *hc, uint8_t enable);
int espi_hc_ctx_get_status(struct espi_hc_context *hc);
int espi_hc_ctx_emu_get_config(struct espi_hc_context *hc, uint16_t cfg_offset);
int espi_hc_ctx_emu_set_config(struct espi_hc_context *hc, uint16_t cfg_offset,
			       uint32_t new_config);

/* Set state of a single VWire at specified host index in the context.
 * Does not transmit VWire. If level changed, set the valid bit.
 * Use another API to transmit.
 */
int espi_hc_set_ct_vwire(struct espi_hc_context *hc, uint8_t host_index,
			 uint8_t src, uint8_t level);

/* Send/Get VWires.
 * vws array of struct espi_vwire
 */
int espi_hc_ctx_emu_put_host_index(struct espi_hc_context *hc, uint8_t host_index);

#define ESPI_HC_EMU_PUT_VW_RST_VAL 0x01
int espi_hc_ctx_emu_put_mult_host_index(struct espi_hc_context *hc, uint8_t *hidxs, uint8_t nhidx,
					uint32_t flags);

int espi_hc_ctx_emu_put_vws(struct espi_hc_context *hc, struct espi_hc_vw *vws, uint8_t nvws);
int espi_hc_ctx_emu_get_vws(struct espi_hc_context *hc, struct espi_hc_vw *vws, uint8_t nvws,
			    uint8_t *nrecv);
int espi_hc_ctx_emu_get_vws2(struct espi_hc_context *hc, struct espi_hc_vw *vws, uint8_t nvws,
			     uint8_t *nrecv);

int espi_hc_ctx_emu_update_t2c_vw(struct espi_hc_context *hc, struct espi_hc_vw *vws, uint8_t nvws);

int espi_hc_get_vw_group_data(struct espi_hc_context *hc, uint8_t host_index,
			      struct espi_hc_vw *vwgroup);

int espi_hc_emu_get_status(struct espi_hc_context *hc, uint16_t *espi_status);
int espi_hc_emu_get_config(struct espi_hc_context *hc, uint16_t config_offset,
			   uint32_t *config, uint16_t *cmd_status);
int espi_hc_emu_set_config(struct espi_hc_context *hc, uint16_t config_offset,
			   uint32_t config, uint16_t *cmd_status);

/* Peripheral Channel */
int espi_hc_emu_put_iowr(struct espi_hc_context *hc, uint32_t io_addr_len,
			 uint32_t data, uint16_t *cmd_status);
int espi_hc_emu_put_iord(struct espi_hc_context *hc, uint32_t io_addr_len,
			 uint32_t *data, uint16_t *cmd_status);

#endif /* __SAMPLES_BOARDS_MEC_ASSY6906_ESPI_HC_EMU_H_ */
```
